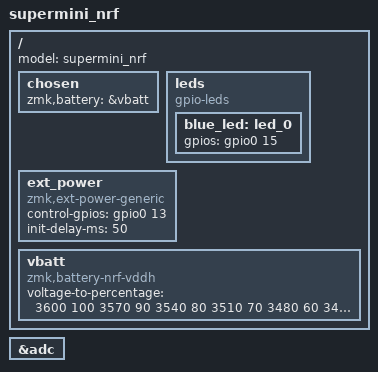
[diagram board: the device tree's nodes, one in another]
/*
 * Copyright (c) 2021 The ZMK Contributors
 *
 * SPDX-License-Identifier: MIT
 */

/dts-v1/;
#include "supermini_nrf.dtsi"

/ {
    model = "supermini_nrf";
    chosen {
        zmk,battery = &vbatt;
    };
    
    leds {
        compatible = "gpio-leds";
        blue_led: led_0 {
            gpios = <&gpio0 15 GPIO_ACTIVE_HIGH>;
        };
    };

    // Node name must match original "EXT_POWER" label to preserve user settings.
    ext_power: ext_power {
        compatible = "zmk,ext-power-generic";
        control-gpios = <&gpio0 13 GPIO_ACTIVE_HIGH>;
        init-delay-ms = <50>;
    }; 
    // aliases {
    //     battery = &vbatt;
    // };

    vbatt: vbatt {
    compatible = "zmk,battery-nrf-vddh";
        voltage-to-percentage = <
            3600 100
            3570 90
            3540 80
            3510 70
            3480 60
            3450 50
            3420 40
            3390 30
            3360 20
            3330 10
            3300 0
        >;
    };

    // vbatt: vbatt {
    //     compatible = "zmk,battery-nrf-vddh";
    //     io-channels = <&adc 0>;
    //     output-ohms = <100000>;
    //     full-ohms = <100000>;
    // };
    
};
&adc {
    status = "okay";
    // battery_voltage: battery_voltage {
    //     io-channels = <&adc 0>; /* Assuming you use ADC channel 0 */
    //     input-positive = <NRF_SAADC_INPUT_AIN0>;
    //     /* if voltage divider exists: define ratio */
    //     zephyr,voltage-divider = <100 100>; /* example 2:1 divider */
    // };
};
// &zephyr_battery {
//     io-channels = <&adc 0>; /* ADC channel 0 */
//     input-pin = <31>; /* P0.31 */
//     voltage-to-percentage = <
//         4200 100
//         4100 90
//         4000 80
//         3900 65
//         3800 50
//         3700 30
//         3600 10
//         3500 0
//     >;
// };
